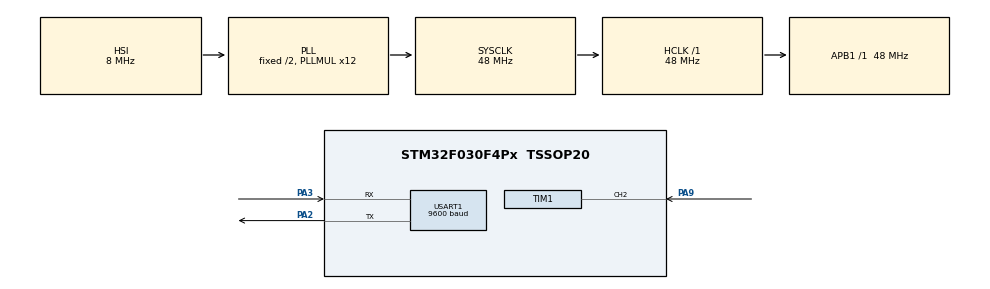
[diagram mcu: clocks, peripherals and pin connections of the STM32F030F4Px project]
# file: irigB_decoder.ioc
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Dma.Request0=USART1_TX
Dma.USART1_TX.0.Direction=DMA_MEMORY_TO_PERIPH
Dma.USART1_TX.0.Instance=DMA1_Channel2
Dma.USART1_TX.0.MemDataAlignment=DMA_MDATAALIGN_BYTE
Dma.USART1_TX.0.MemInc=DMA_MINC_ENABLE
Dma.USART1_TX.0.Mode=DMA_NORMAL
Dma.USART1_TX.0.PeriphDataAlignment=DMA_PDATAALIGN_BYTE
Dma.USART1_TX.0.PeriphInc=DMA_PINC_DISABLE
Dma.USART1_TX.0.Priority=DMA_PRIORITY_LOW
Mcu.Family=STM32F0
Mcu.Name=STM32F030F4Px
Mcu.Package=TSSOP20
NVIC.DMA1_Channel2_3_IRQn=true\:0\:0\:false\:false\:true\:false\:true
NVIC.TIM1_CC_IRQn=true\:0\:0\:false\:false\:true\:true\:true
PA13.Mode=Serial_Wire
PA13.Signal=SYS_SWDIO
PA14.Mode=Serial_Wire
PA14.Signal=SYS_SWCLK
PA2.Mode=Asynchronous
PA2.Signal=USART1_TX
PA3.Mode=Asynchronous
PA3.Signal=USART1_RX
PA9.Signal=S_TIM1_CH2
ProjectManager.HeapSize=0x200
ProjectManager.StackSize=0x400
ProjectManager.TargetToolchain=STM32CubeIDE
RCC.AHBFreq_Value=48000000
RCC.APB1Freq_Value=48000000
RCC.APB1TimFreq_Value=48000000
RCC.HCLKFreq_Value=48000000
RCC.PLLMUL=RCC_PLL_MUL12
RCC.SYSCLKFreq_VALUE=48000000
RCC.SYSCLKSource=RCC_SYSCLKSOURCE_PLLCLK
SH.S_TIM1_CH2.0=TIM1_CH2,Input_Capture2_from_TI2
TIM1.Channel-Input_Capture2_from_TI2=TIM_CHANNEL_2
TIM1.ICPolarity_CH2=TIM_INPUTCHANNELPOLARITY_BOTHEDGE
TIM1.Prescaler=48
USART1.BaudRate=9600
USART1.VirtualMode-Asynchronous=VM_ASYNC
VP_TIM1_VS_ClockSourceINT.Mode=Internal
board=custom

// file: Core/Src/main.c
/* USER CODE BEGIN Header */
/**
  ******************************************************************************
  * @file           : main.c
  * @brief          : Main program body
  ******************************************************************************
  * @attention
  *
  * <h2><center>&copy; Copyright (c) 2021 STMicroelectronics.
  * All rights reserved.</center></h2>
  *
  * This software component is licensed by ST under BSD 3-Clause license,
  * the "License"; You may not use this file except in compliance with the
  * License. You may obtain a copy of the License at:
  *                        opensource.org/licenses/BSD-3-Clause
  *
  ******************************************************************************
  */
/* USER CODE END Header */
#include "main.h"

/* USER CODE BEGIN Includes */
#include "irigB.h"
/* USER CODE END Includes */

TIM_HandleTypeDef htim1;

UART_HandleTypeDef huart1;
DMA_HandleTypeDef hdma_usart1_tx;

void SystemClock_Config(void);
static void MX_GPIO_Init(void);
static void MX_DMA_Init(void);
static void MX_TIM1_Init(void);
static void MX_USART1_UART_Init(void);

/* USER CODE BEGIN 0 */

/*
 * Timer interrupt handler
 * The timer is set up to run at 1MHz -> 1uS resolution
 */
void HAL_TIM_IC_CaptureCallback(TIM_HandleTypeDef *htim)
{
	static uint32_t microSeconds = 0;
	static uint8_t polarity = 1;
	if(htim->Channel == HAL_TIM_ACTIVE_CHANNEL_2)
	{
		if(polarity == 1) /* Capture on rising edge */
		{
			/* Reset the timer */
			polarity = 0;
			__HAL_TIM_SET_COUNTER(&htim1, 0);
			/* Set the timer to capture on a falling edge (acquire pulse length) */
			__HAL_TIM_SET_CAPTUREPOLARITY(&htim1, TIM_CHANNEL_2, TIM_INPUTCHANNELPOLARITY_FALLING);
			return;
		}
		else /* Capture on falling edge, get the time interval */
		{
			microSeconds = HAL_TIM_ReadCapturedValue(&htim1, TIM_CHANNEL_2);

			/* Send time interval to the IRIG-B protocol decoder */
			handleInterrupt(microSeconds);
			/* Reset the timer */
			polarity = 1;
			/* This is not needed since we don't use the LOW pulse length, but here it is anyway */
			/* It could be used in order to recreate the frame waveform but it's out of scope right now */
			__HAL_TIM_SET_COUNTER(&htim1, 0);
			/* Set the timer to capture on a rising edge */
			__HAL_TIM_SET_CAPTUREPOLARITY(&htim1, TIM_CHANNEL_2, TIM_INPUTCHANNELPOLARITY_RISING);
			return;
		}
	}
}

/* USER CODE END 0 */

int main(void)
{

  /* MCU Configuration--------------------------------------------------------*/

  /* Reset of all peripherals, Initializes the Flash interface and the Systick. */
  HAL_Init();

  /* Configure the system clock */
  SystemClock_Config();

  /* Initialize all configured peripherals */
  MX_GPIO_Init();
  MX_DMA_Init();
  MX_TIM1_Init();
  MX_USART1_UART_Init();
  /* USER CODE BEGIN 2 */

  /* Start the timer in Input Capture with interrupts, there's where the magic happens */
  HAL_TIM_IC_Start_IT(&htim1, TIM_CHANNEL_2);

  /* USER CODE END 2 */

  /* Infinite loop */
  /* USER CODE BEGIN WHILE */
  while (1)
  {
	  /* Nothing to do in the main() loop */
	  HAL_Delay(100);

    /* USER CODE END WHILE */

  }
}

void SystemClock_Config(void)
{
  RCC_OscInitTypeDef RCC_OscInitStruct = {0};
  RCC_ClkInitTypeDef RCC_ClkInitStruct = {0};
  RCC_PeriphCLKInitTypeDef PeriphClkInit = {0};

  /** Initializes the RCC Oscillators according to the specified parameters
  * in the RCC_OscInitTypeDef structure.
  */
  RCC_OscInitStruct.OscillatorType = RCC_OSCILLATORTYPE_HSI;
  RCC_OscInitStruct.HSIState = RCC_HSI_ON;
  RCC_OscInitStruct.HSICalibrationValue = RCC_HSICALIBRATION_DEFAULT;
  RCC_OscInitStruct.PLL.PLLState = RCC_PLL_ON;
  RCC_OscInitStruct.PLL.PLLSource = RCC_PLLSOURCE_HSI;
  RCC_OscInitStruct.PLL.PLLMUL = RCC_PLL_MUL12;
  RCC_OscInitStruct.PLL.PREDIV = RCC_PREDIV_DIV1;
  if (HAL_RCC_OscConfig(&RCC_OscInitStruct) != HAL_OK)
  {
    Error_Handler();
  }
  /** Initializes the CPU, AHB and APB buses clocks
  */
  RCC_ClkInitStruct.ClockType = RCC_CLOCKTYPE_HCLK|RCC_CLOCKTYPE_SYSCLK
                              |RCC_CLOCKTYPE_PCLK1;
  RCC_ClkInitStruct.SYSCLKSource = RCC_SYSCLKSOURCE_PLLCLK;
  RCC_ClkInitStruct.AHBCLKDivider = RCC_SYSCLK_DIV1;
  RCC_ClkInitStruct.APB1CLKDivider = RCC_HCLK_DIV1;

  if (HAL_RCC_ClockConfig(&RCC_ClkInitStruct, FLASH_LATENCY_1) != HAL_OK)
  {
    Error_Handler();
  }
  PeriphClkInit.PeriphClockSelection = RCC_PERIPHCLK_USART1;
  PeriphClkInit.Usart1ClockSelection = RCC_USART1CLKSOURCE_PCLK1;
  if (HAL_RCCEx_PeriphCLKConfig(&PeriphClkInit) != HAL_OK)
  {
    Error_Handler();
  }
}

static void MX_TIM1_Init(void)
{

  TIM_ClockConfigTypeDef sClockSourceConfig = {0};
  TIM_MasterConfigTypeDef sMasterConfig = {0};
  TIM_IC_InitTypeDef sConfigIC = {0};

  htim1.Instance = TIM1;
  htim1.Init.Prescaler = 48;
  htim1.Init.CounterMode = TIM_COUNTERMODE_UP;
  htim1.Init.Period = 65535;
  htim1.Init.ClockDivision = TIM_CLOCKDIVISION_DIV1;
  htim1.Init.RepetitionCounter = 0;
  htim1.Init.AutoReloadPreload = TIM_AUTORELOAD_PRELOAD_DISABLE;
  if (HAL_TIM_Base_Init(&htim1) != HAL_OK)
  {
    Error_Handler();
  }
  sClockSourceConfig.ClockSource = TIM_CLOCKSOURCE_INTERNAL;
  if (HAL_TIM_ConfigClockSource(&htim1, &sClockSourceConfig) != HAL_OK)
  {
    Error_Handler();
  }
  if (HAL_TIM_IC_Init(&htim1) != HAL_OK)
  {
    Error_Handler();
  }
  sMasterConfig.MasterOutputTrigger = TIM_TRGO_RESET;
  sMasterConfig.MasterSlaveMode = TIM_MASTERSLAVEMODE_DISABLE;
  if (HAL_TIMEx_MasterConfigSynchronization(&htim1, &sMasterConfig) != HAL_OK)
  {
    Error_Handler();
  }
  sConfigIC.ICPolarity = TIM_INPUTCHANNELPOLARITY_BOTHEDGE;
  sConfigIC.ICSelection = TIM_ICSELECTION_DIRECTTI;
  sConfigIC.ICPrescaler = TIM_ICPSC_DIV1;
  sConfigIC.ICFilter = 0;
  if (HAL_TIM_IC_ConfigChannel(&htim1, &sConfigIC, TIM_CHANNEL_2) != HAL_OK)
  {
    Error_Handler();
  }

}

static void MX_USART1_UART_Init(void)
{

  huart1.Instance = USART1;
  huart1.Init.BaudRate = 9600;
  huart1.Init.WordLength = UART_WORDLENGTH_8B;
  huart1.Init.StopBits = UART_STOPBITS_1;
  huart1.Init.Parity = UART_PARITY_NONE;
  huart1.Init.Mode = UART_MODE_TX_RX;
  huart1.Init.HwFlowCtl = UART_HWCONTROL_NONE;
  huart1.Init.OverSampling = UART_OVERSAMPLING_16;
  huart1.Init.OneBitSampling = UART_ONE_BIT_SAMPLE_DISABLE;
  huart1.AdvancedInit.AdvFeatureInit = UART_ADVFEATURE_NO_INIT;
  if (HAL_UART_Init(&huart1) != HAL_OK)
  {
    Error_Handler();
  }

}

static void MX_DMA_Init(void)
{

  /* DMA controller clock enable */
  __HAL_RCC_DMA1_CLK_ENABLE();

  /* DMA interrupt init */
  /* DMA1_Channel2_3_IRQn interrupt configuration */
  HAL_NVIC_SetPriority(DMA1_Channel2_3_IRQn, 0, 0);
  HAL_NVIC_EnableIRQ(DMA1_Channel2_3_IRQn);

}

static void MX_GPIO_Init(void)
{

  /* GPIO Ports Clock Enable */
  __HAL_RCC_GPIOA_CLK_ENABLE();

}

void Error_Handler(void)
{
  __disable_irq();
  while (1)
  {
  }
}

/************************ (C) COPYRIGHT STMicroelectronics *****END OF FILE****/
